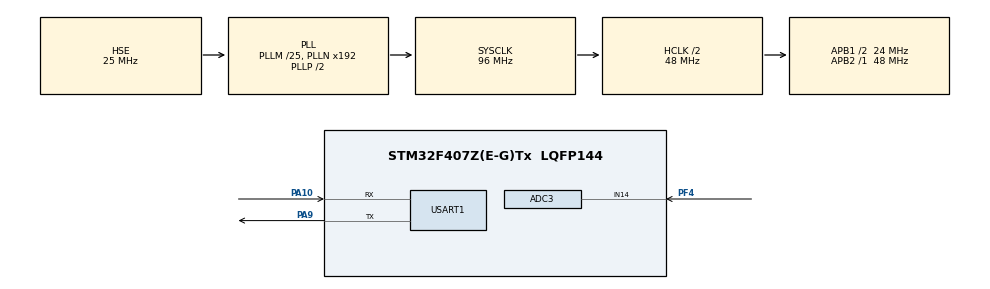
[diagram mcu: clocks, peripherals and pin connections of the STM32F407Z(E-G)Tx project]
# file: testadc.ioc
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ADC3.Channel-0\#ChannelRegularConversion=ADC_CHANNEL_14
ADC3.ContinuousConvMode=ENABLE
ADC3.DMAContinuousRequests=ENABLE
ADC3.NbrOfConversionFlag=1
ADC3.Rank-0\#ChannelRegularConversion=1
ADC3.SamplingTime-0\#ChannelRegularConversion=ADC_SAMPLETIME_28CYCLES
ADC3.ScanConvMode=ENABLE
Dma.ADC3.0.Direction=DMA_PERIPH_TO_MEMORY
Dma.ADC3.0.FIFOMode=DMA_FIFOMODE_DISABLE
Dma.ADC3.0.Instance=DMA2_Stream0
Dma.ADC3.0.MemDataAlignment=DMA_MDATAALIGN_HALFWORD
Dma.ADC3.0.MemInc=DMA_MINC_ENABLE
Dma.ADC3.0.Mode=DMA_CIRCULAR
Dma.ADC3.0.PeriphDataAlignment=DMA_PDATAALIGN_HALFWORD
Dma.ADC3.0.PeriphInc=DMA_PINC_DISABLE
Dma.ADC3.0.Priority=DMA_PRIORITY_LOW
Dma.Request0=ADC3
Mcu.Family=STM32F4
Mcu.Name=STM32F407Z(E-G)Tx
Mcu.Package=LQFP144
NVIC.ADC_IRQn=true\:0\:0\:false\:false\:true\:true\:true
NVIC.DMA2_Stream0_IRQn=true\:0\:0\:false\:false\:true\:false\:true
NVIC.PriorityGroup=NVIC_PRIORITYGROUP_4
NVIC.RCC_IRQn=true\:0\:0\:false\:false\:true\:true\:false
NVIC.USART1_IRQn=true\:0\:0\:false\:false\:true\:true\:true
PA10.Mode=Asynchronous
PA10.Signal=USART1_RX
PA13.Mode=Serial_Wire
PA13.Signal=SYS_JTMS-SWDIO
PA14.Mode=Serial_Wire
PA14.Signal=SYS_JTCK-SWCLK
PA9.Mode=Asynchronous
PA9.Signal=USART1_TX
PC14-OSC32_IN.Mode=LSE-External-Oscillator
PC14-OSC32_IN.Signal=RCC_OSC32_IN
PC15-OSC32_OUT.Mode=LSE-External-Oscillator
PC15-OSC32_OUT.Signal=RCC_OSC32_OUT
PF4.Mode=IN14
PF4.Signal=ADC3_IN14
PH0-OSC_IN.Mode=HSE-External-Oscillator
PH0-OSC_IN.Signal=RCC_OSC_IN
PH1-OSC_OUT.Mode=HSE-External-Oscillator
PH1-OSC_OUT.Signal=RCC_OSC_OUT
ProjectManager.HeapSize=0x200
ProjectManager.StackSize=0x400
ProjectManager.TargetToolchain=TrueSTUDIO
RCC.48MHZClocksFreq_Value=48000000
RCC.AHBCLKDivider=RCC_SYSCLK_DIV2
RCC.AHBFreq_Value=48000000
RCC.APB1CLKDivider=RCC_HCLK_DIV2
RCC.APB1Freq_Value=24000000
RCC.APB1TimFreq_Value=48000000
RCC.APB2Freq_Value=48000000
RCC.APB2TimFreq_Value=48000000
RCC.CortexFreq_Value=48000000
RCC.HCLKFreq_Value=48000000
RCC.HSE_VALUE=25000000
RCC.HSI_VALUE=16000000
RCC.PLLM=25
RCC.PLLSourceVirtual=RCC_PLLSOURCE_HSE
RCC.SYSCLKFreq_VALUE=96000000
RCC.SYSCLKSource=RCC_SYSCLKSOURCE_PLLCLK
RCC.VCOOutputFreq_Value=192000000
USART1.VirtualMode=VM_ASYNC
board=custom

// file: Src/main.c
/* USER CODE BEGIN Header */
/**
  ******************************************************************************
  * @file           : main.c
  * @brief          : Main program body
  ******************************************************************************
  * @attention
  *
  * <h2><center>&copy; Copyright (c) 2019 STMicroelectronics.
  * All rights reserved.</center></h2>
  *
  * This software component is licensed by ST under BSD 3-Clause license,
  * the "License"; You may not use this file except in compliance with the
  * License. You may obtain a copy of the License at:
  *                        opensource.org/licenses/BSD-3-Clause
  *
  ******************************************************************************
  */
/* USER CODE END Header */

#include "main.h"
#include "adc.h"
#include "dma.h"
#include "usart.h"
#include "gpio.h"

/* USER CODE BEGIN Includes */
//#include <stdio.h>
/* USER CODE END Includes */

void SystemClock_Config(void);
/* USER CODE BEGIN PFP */
#ifdef __GNUC__
/* With GCC/RAISONANCE, small printf (option LD Linker->Libraries->Small printf
   set to 'Yes') calls __io_putchar() */
#define PUTCHAR_PROTOTYPE int __io_putchar(int ch)
#else
#define PUTCHAR_PROTOTYPE int fputc(int ch, FILE *f)
#endif /* __GNUC__ */

PUTCHAR_PROTOTYPE
{
    /* Place your implementation of fputc here */
    /* e.g. write a character to the Debug USART and Loop until the end of transmission */

    if('\n' == ch)
    {
        int ch_tmp = '\r';

        /* Place your implementation of fputc here */
        /* e.g. write a character to the EVAL_COM1 and Loop until the end of transmission */
        HAL_UART_Transmit(&huart1, (uint8_t *)&ch_tmp, 1, 0xFFFF);
    }

    /* Place your implementation of fputc here */
    /* e.g. write a character to the EVAL_COM1 and Loop until the end of transmission */
    HAL_UART_Transmit(&huart1, (uint8_t *)&ch, 1, 0xFFFF);

    return ch;
}
/* USER CODE END PFP */

int main(void)
{
  /* USER CODE BEGIN 1 */
	uint32_t adcvalue[1];
  /* USER CODE END 1 */

  /* MCU Configuration--------------------------------------------------------*/

  /* Reset of all peripherals, Initializes the Flash interface and the Systick. */
  HAL_Init();

  /* Configure the system clock */
  SystemClock_Config();

  /* Initialize all configured peripherals */
  MX_GPIO_Init();
  MX_DMA_Init();
  MX_ADC3_Init();
  MX_USART1_UART_Init();
  /* USER CODE BEGIN 2 */
  HAL_ADC_Start_DMA(&hadc3,&adcvalue[0],1 );

  /* USER CODE END 2 */

  /* Infinite loop */
  /* USER CODE BEGIN WHILE */
  //HAL_UART_Transmit_IT(&huart1,"ab /r/n",3);
  while (1)
  {
    /* USER CODE END WHILE */

    /* USER CODE BEGIN 3 */
	printf("ab ");
	  //  HAL_UART_Transmit_IT(&huart1,"ab ",3);
//	  HAL_UART_Transmit_IT(&huart1,"ab /r/n",3);
//	  HAL_UART_Transmit(&huart1,"ab /r/n",sizeof("ab /r/n"), 10);
  }
  /* USER CODE END 3 */
}

void SystemClock_Config(void)
{
  RCC_OscInitTypeDef RCC_OscInitStruct = {0};
  RCC_ClkInitTypeDef RCC_ClkInitStruct = {0};

  /** Configure the main internal regulator output voltage
  */
  __HAL_RCC_PWR_CLK_ENABLE();
  __HAL_PWR_VOLTAGESCALING_CONFIG(PWR_REGULATOR_VOLTAGE_SCALE1);
  /** Initializes the CPU, AHB and APB busses clocks
  */
  RCC_OscInitStruct.OscillatorType = RCC_OSCILLATORTYPE_HSE;
  RCC_OscInitStruct.HSEState = RCC_HSE_ON;
  RCC_OscInitStruct.PLL.PLLState = RCC_PLL_ON;
  RCC_OscInitStruct.PLL.PLLSource = RCC_PLLSOURCE_HSE;
  RCC_OscInitStruct.PLL.PLLM = 25;
  RCC_OscInitStruct.PLL.PLLN = 192;
  RCC_OscInitStruct.PLL.PLLP = RCC_PLLP_DIV2;
  RCC_OscInitStruct.PLL.PLLQ = 4;
  if (HAL_RCC_OscConfig(&RCC_OscInitStruct) != HAL_OK)
  {
    Error_Handler();
  }
  /** Initializes the CPU, AHB and APB busses clocks
  */
  RCC_ClkInitStruct.ClockType = RCC_CLOCKTYPE_HCLK|RCC_CLOCKTYPE_SYSCLK
                              |RCC_CLOCKTYPE_PCLK1|RCC_CLOCKTYPE_PCLK2;
  RCC_ClkInitStruct.SYSCLKSource = RCC_SYSCLKSOURCE_PLLCLK;
  RCC_ClkInitStruct.AHBCLKDivider = RCC_SYSCLK_DIV2;
  RCC_ClkInitStruct.APB1CLKDivider = RCC_HCLK_DIV2;
  RCC_ClkInitStruct.APB2CLKDivider = RCC_HCLK_DIV1;

  if (HAL_RCC_ClockConfig(&RCC_ClkInitStruct, FLASH_LATENCY_1) != HAL_OK)
  {
    Error_Handler();
  }
}

void Error_Handler(void)
{
}

/************************ (C) COPYRIGHT STMicroelectronics *****END OF FILE****/
